# cslr_chip register map
Vendor: Texas Instruments
Peripheral module from a debugger description file (folder TCI6484_C6457).
Registers are 32-bit, access not given, reset 0x0 unless marked. A register's access mark holds for its fields unless they carry their own. Offsets are as the file gives them; lines under a group give offsets from that group; [hi:lo] are bit positions; {n}, {i} and the like mark numbered series; 'fields as' and 'values as' point back to an identical list; <NAME> marks a mode.

## CHIP
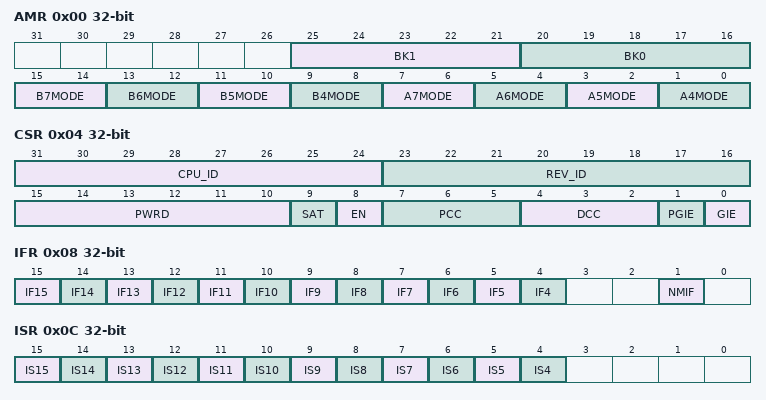
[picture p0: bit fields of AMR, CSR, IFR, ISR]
0x00 AMR — Addressing mode register
  [25:21] BK1 rw — Block size 1
  [20:16] BK0 rw — Block size 0
  [15:14] B7MODE rw
    0=LINEAR; 1=CIRCULARBK0; 2=CIRCULARBK1
  [13:12] B6MODE rw
    0=LINEAR; 1=CIRCULARBK0; 2=CIRCULARBK1
  [11:10] B5MODE rw
    0=LINEAR; 1=CIRCULARBK1; 2=CIRCULARBK2
  [9:8] B4MODE rw
    0=LINEAR; 1=CIRCULARBK1; 2=CIRCULARBK2
  [7:6] A7MODE rw
    0=LINEAR; 1=CIRCULARBK1; 2=CIRCULARBK2
  [5:4] A6MODE rw
    0=LINEAR; 1=CIRCULARBK2; 2=CIRCULARBK3
  [3:2] A5MODE rw
    0=LINEAR; 1=CIRCULARBK3; 2=CIRCULARBK4
  [1:0] A4MODE rw
    0=LINEAR; 1=CIRCULARBK4; 2=CIRCULARBK5
0x04 CSR access per field (reset mask 0xFF00FEFF) — Control status register
  [31:24] CPU_ID ro
  [23:16] REV_ID ro — Revision ID
  [15:10] PWRD ro — Control power-down modes
  [9] SAT rw — Saturate
    1=SATURATE; 0=NONSATURATE
  [8] EN ro — Endianness
    0=BIG; 1=LITTLE
  [7:5] PCC ro — Program Cache control mode
  [4:2] DCC ro — Data Cache control mode
  [1] PGIE ro — Previous GIE
  [0] GIE rw — Global interrupt enable
    1=ENABLE; 0=DISABLE
0x08 IFR — Interrupt Flag Register
  [15] IF15 ro — Interrupt flag 15
    1=ENABLE
  [n] IF{n} ro (n=4..14) — Interrupt flag {n}
  [1] NMIF ro — Non maskable Interrupt flag
0x0C ISR — Interrupt Set Register
  [15] IS15 rw — Interrupt 15 Set
    1=SET (Set Interrupt 15)
  [14] IS14 rw — Interrupt 14 Set
    1=SET (Set Interrupt 14)
  [13] IS13 rw — Interrupt 15 Set
    1=SET (Set Interrupt 13)
  [12] IS12 rw — Interrupt 14 Set
    1=SET (Set Interrupt 12)
  [11] IS11 rw — Interrupt 15 Set
    1=SET (Set Interrupt 11)
  [10] IS10 rw — Interrupt 14 Set
    1=SET (Set Interrupt 10)
  [9] IS9 rw — Interrupt 15 Set
    1=SET (Set Interrupt 9)
  [8] IS8 rw — Interrupt 14 Set
    1=SET (Set Interrupt 8)
  [7] IS7 rw — Interrupt 15 Set
    1=SET (Set Interrupt 7)
  [6] IS6 rw — Interrupt 14 Set
    1=SET (Set Interrupt 6)
  [5] IS5 rw — Interrupt 15 Set
    1=SET (Set Interrupt 5)
  [4] IS4 rw — Interrupt 15 Set
    1=SET (Set Interrupt 4)
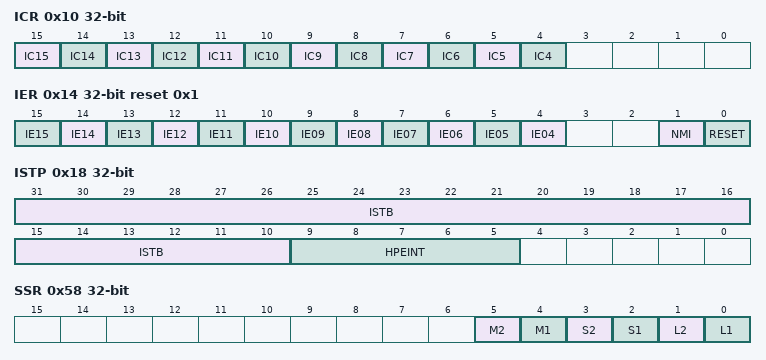
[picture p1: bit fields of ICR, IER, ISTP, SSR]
0x10 ICR — Interrupt clear Register
  [15] IC15 rw — Interrupt 15 Clear
    1=CLR (Clear Interrupt 15)
  [14] IC14 rw — Interrupt 14 Clear
    1=CLR (Clear Interrupt 14)
  [13] IC13 rw — Interrupt 15 Clear
    1=CLR (Clear Interrupt 13)
  [12] IC12 rw — Interrupt 14 Clear
    1=CLR (Clear Interrupt 12)
  [11] IC11 rw — Interrupt 15 Clear
    1=CLR (Clear Interrupt 11)
  [10] IC10 rw — Interrupt 14 Clear
    1=CLR (Clear Interrupt 10)
  [9] IC9 rw — Interrupt 15 Clear
    1=CLR (Clear Interrupt 9)
  [8] IC8 rw — Interrupt 14 Clear
    1=CLR (Clear Interrupt 8)
  [7] IC7 rw — Interrupt 15 Clear
    1=CLR (Clear Interrupt 7)
  [6] IC6 rw — Interrupt 14 Clear
    1=CLR (Clear Interrupt 6)
  [5] IC5 rw — Interrupt 15 Clear
    1=CLR (Clear Interrupt 5)
  [4] IC4 rw — Interrupt 14 Clear
    1=CLR (Clear Interrupt 4)
0x14 IER reset 0x1 — Interrupt enable Register
  [n] IE{n:02} rw (n=4..15) — Interrupt enable {n}
    1=ENABLE; 0=DISABLE
  [1] NMI rw — Non maskable interrupt
    1=ENABLE
  [0] RESET ro — Reset interrupt enable. You cannot disable the reset interrupt.
0x18 ISTP — Interrupt service table pointer
  [31:10] ISTB rw — Interrupt Service table base address
  [9:5] HPEINT rw — Specific interrupt occurred
0x1C IRP rw — Interrupt return pointer
0x20 NRP rw — Non maskable interrupt
0x24 ERP rw — Exception return pointer
0x2C TSCL rw — Low half of 64-bit timestamp
0x30 TSCH rw — High half of 64-bit timestamp
0x38 ILC rw — Inner loop SPL buffer count
  [31:0] ILC — Internal loop SPL buffer count
0x3C RILC rw — Reload Inner loop SPL buffer count
  [31:0] RILC — Reload internal loop SPL buffer count
0x44 PCE1 rw — Program counter E1 phase
  [31:0] PCE1 — Program counter, E1 phase
0x48 DNUM — DSP Number
  [7:0] DSPNUM ro
0x58 SSR access per field — Saturation status register
  [5] M2 rw — Saturation in M2 Unit
  [4] M1 rw — Saturation in M1 Unit
  [3] S2 rw — Saturation in S2 Unit
  [2] S1 rw — Saturation in S1 Unit
  [1] L2 rw — Saturation in L2 Unit
  [0] L1 rw — Saturation in L1 Unit
0x5C GPLYA rw — GMPY polynomial for A-side
0x60 GPLYB rw — GMPY polynomial for B-side
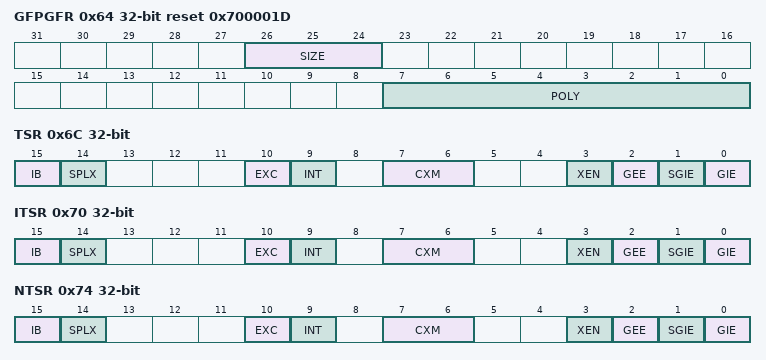
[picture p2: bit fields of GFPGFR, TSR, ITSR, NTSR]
0x64 GFPGFR reset 0x700001D — Galois field multiply control register
  [26:24] SIZE rw
  [7:0] POLY rw — Polynomial
0x6C TSR — Task state register
  [15] IB ro — Interrupts blocked
    0=UNBLOCKED; 1=BLOCKED
  [14] SPLX ro — SPLOOP Executing
    0=NOTEXEC; 1=EXEC
  [10] EXC ro — Execption Processing
    0=NOTEXEC; 1=EXEC
  [9] INT rw — Interrupt Processing
    0=NOTEXEC; 1=EXEC
  [7:6] CXM ro — Current Execution Mode
    0=SUPERVISOR; 1=USER
  [3] XEN rw — Maskable exception enable
    1=ENABLE; 0=DISABLE
  [2] GEE rw — Globale exception enable
    1=ENABLE; 0=DISABLE
  [1] SGIE rw — Saved global interrupt enable
  [0] GIE rw — Global interrupt enable
    1=ENABLE; 0=DISABLE
0x70 ITSR — Interrupt task state register
  fields as TSR
0x74 NTSR — Non maskable TSR snapshot
  fields as TSR
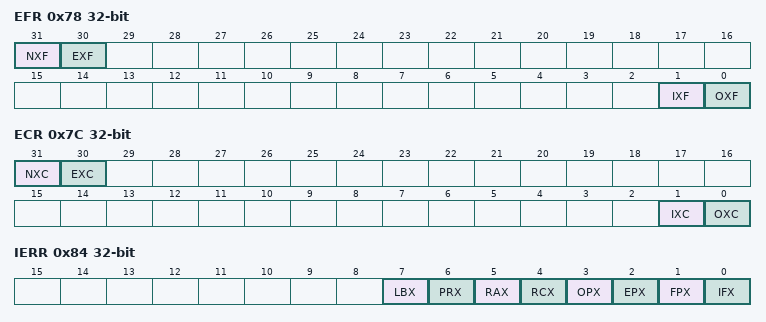
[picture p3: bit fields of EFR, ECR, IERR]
0x78 EFR — Exception Flag Register
  [31] NXF rw — NMI Exception flag
  [30] EXF rw — EXCEP Exception flag
  [1] IXF rw — Internal Exception flag
  [0] OXF rw — OSSR Exception flag
0x7C ECR — Exception clear register
  [all] fields
    1=CLEAR
  [31] NXC rw — NMI Exception Clear
  [30] EXC rw — EXCEP Exception Clear
  [1] IXC rw — Internal Exception Clear
  [0] OXC rw — OSSR Exception Clear
0x84 IERR — Internal exception cause register
  [7] LBX rw — SPLOOP buffer exception
  [6] PRX rw — Privilege exception
  [5] RAX rw — Resource access exception
  [4] RCX rw — Resource conflict exception
  [3] OPX rw — Opcode exception
  [2] EPX rw — Execute packet exception
  [1] FPX rw — Fetch packet exception
  [0] IFX rw — Instruction fetch exception
0x88 REP rw — Restricted entry point address register
